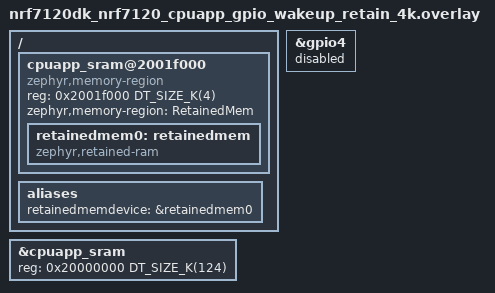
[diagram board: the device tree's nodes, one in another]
#include "nrf7120dk_nrf7120_cpuapp_gpio_wakeup.overlay"

/ {
	cpuapp_sram@2001f000 {
		compatible = "zephyr,memory-region", "mmio-sram";
		reg = <0x2001f000 DT_SIZE_K(4)>;
		zephyr,memory-region = "RetainedMem";
		status = "okay";

		retainedmem0: retainedmem {
			compatible = "zephyr,retained-ram";
			status = "okay";
		};
	};

	aliases {
		retainedmemdevice = &retainedmem0;
	};
};

&cpuapp_sram {
	/* Shrink SRAM size to avoid overlap with retained memory region */
	reg = <0x20000000 DT_SIZE_K(124)>;
	ranges = <0x0 0x20000000 0x1f000>;
};

&gpio4 {
	status = "disabled";
};
